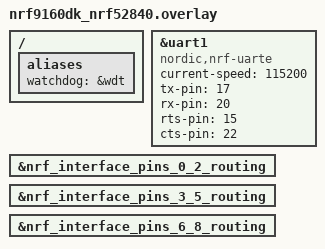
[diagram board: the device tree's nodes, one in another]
// To get started, press Ctrl+Space to bring up the completion menu and view the available nodes.
// For more help, browse the DeviceTree documentation at https: //docs.zephyrproject.org/latest/guides/dts/index.html
&uart1 {
	compatible = "nordic,nrf-uarte";
	current-speed = <115200>;
	status = "okay";
	tx-pin = <17>;
	rx-pin = <20>;
	rts-pin = <15>;
	cts-pin = <22>;
};

&nrf_interface_pins_0_2_routing {
	status = "okay";
};

&nrf_interface_pins_3_5_routing {
	status = "okay";
};

&nrf_interface_pins_6_8_routing {
	status = "okay";
};

/ { 
    aliases {
	watchdog = &wdt;
};

};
